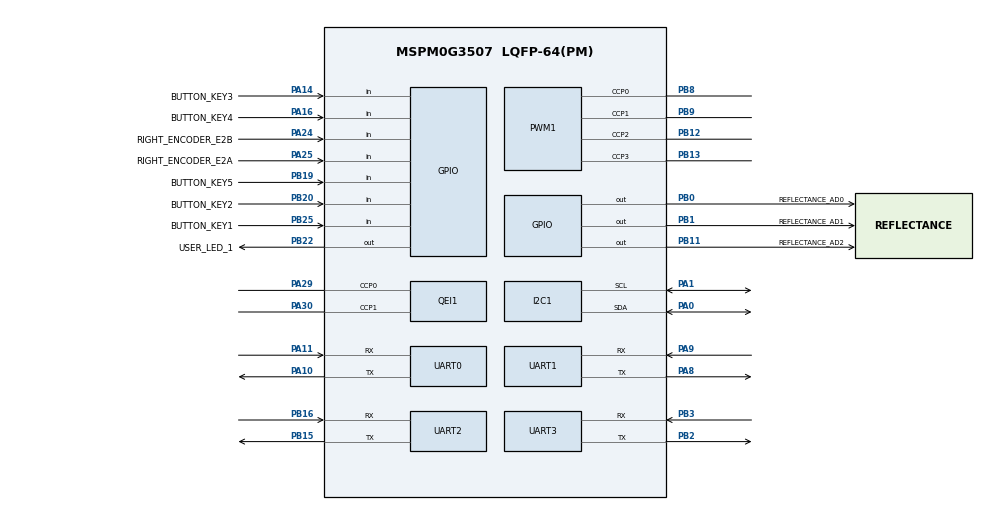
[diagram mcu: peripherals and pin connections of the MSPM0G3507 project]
/**
 * ECHO platform configuration.
 * 80 MHz MCLK, 1 MHz TIMG12 timebase, and Tianmengxing PB22 LED.
 */
//@cliArgs --device "MSPM0G350X" --package "LQFP-64(PM)" --part "Default"
//@v2CliArgs --device "MSPM0G3507" --package "LQFP-64(PM)"
// @cliArgs --board /ti/boards/LP_MSPM0G3507 --rtos freertos

const ProjectConfig = scripting.addModule("/ti/project_config/ProjectConfig");
const ADC12  = scripting.addModule("/ti/driverlib/ADC12", {}, false);
const ADC1   = ADC12.addInstance();
const ADC2   = ADC12.addInstance();
const GPIO   = scripting.addModule("/ti/driverlib/GPIO", {}, false);
const GPIO1  = GPIO.addInstance();
const GPIO2  = GPIO.addInstance();
const GPIO3  = GPIO.addInstance();
const GPIO4  = GPIO.addInstance();
const GPIO5  = GPIO.addInstance();
const I2C    = scripting.addModule("/ti/driverlib/I2C", {}, false);
const I2C1   = I2C.addInstance();
const PWM    = scripting.addModule("/ti/driverlib/PWM", {}, false);
const PWM1   = PWM.addInstance();
const QEI    = scripting.addModule("/ti/driverlib/QEI", {}, false);
const QEI1   = QEI.addInstance();
const SYSCTL = scripting.addModule("/ti/driverlib/SYSCTL");
const TIMER  = scripting.addModule("/ti/driverlib/TIMER", {}, false);
const TIMER1 = TIMER.addInstance();

ProjectConfig.genDisable = true;

const pllClk1Divider = system.clockTree["PLL_CLK1_DIV"];
pllClk1Divider.divideValue = 4;

const pllClk2xDivider = system.clockTree["PLL_CLK2X_DIV"];
pllClk2xDivider.divideValue = 4;

const pllPDivider = system.clockTree["PLL_PDIV"];
pllPDivider.divideValue = 2;

const ulpClkDivider = system.clockTree["UDIV"];
ulpClkDivider.divideValue = 2;

const pllQDivider = system.clockTree["PLL_QDIV"];
pllQDivider.multiplyValue = 10;

const hsclkMux = system.clockTree["HSCLKMUX"];
hsclkMux.inputSelect = "HSCLKMUX_SYSPLL2X";

const mfclkGate = system.clockTree["MFCLKGATE"];
mfclkGate.enable = true;

GPIO1.$name                          = "GPIO_LEDS";
GPIO1.associatedPins[0].$name        = "USER_LED_1";
GPIO1.associatedPins[0].assignedPin  = "22";
GPIO1.associatedPins[0].initialValue = "SET";
GPIO1.associatedPins[0].internalResistor = "PULL_DOWN";
GPIO1.associatedPins[0].pin.$assign  = "PB22";

GPIO2.$name                         = "GPIO_RIGHT_ENCODER";
GPIO2.associatedPins.create(2);
GPIO2.associatedPins[0].$name       = "RIGHT_ENCODER_E2A";
GPIO2.associatedPins[0].direction   = "INPUT";
GPIO2.associatedPins[0].interruptEn = true;
GPIO2.associatedPins[0].polarity    = "RISE";
GPIO2.associatedPins[0].pin.$assign = "PA25";
GPIO2.associatedPins[1].$name       = "RIGHT_ENCODER_E2B";
GPIO2.associatedPins[1].direction   = "INPUT";
GPIO2.associatedPins[1].pin.$assign = "PA24";

GPIO3.$name                         = "GPIO_REFLECTANCE_MUX";
GPIO3.associatedPins.create(3);
GPIO3.associatedPins[0].$name       = "REFLECTANCE_AD0";
GPIO3.associatedPins[0].pin.$assign = "PB0";
GPIO3.associatedPins[1].$name       = "REFLECTANCE_AD1";
GPIO3.associatedPins[1].pin.$assign = "PB1";
GPIO3.associatedPins[2].$name       = "REFLECTANCE_AD2";
GPIO3.associatedPins[2].pin.$assign = "PB11";

GPIO4.$name                         = "GPIO_BUTTONS_A";
GPIO4.associatedPins.create(2);
GPIO4.associatedPins[0].$name       = "BUTTON_KEY3";
GPIO4.associatedPins[0].direction   = "INPUT";
GPIO4.associatedPins[0].internalResistor = "PULL_UP";
GPIO4.associatedPins[0].pin.$assign = "PA14";
GPIO4.associatedPins[1].$name       = "BUTTON_KEY4";
GPIO4.associatedPins[1].direction   = "INPUT";
GPIO4.associatedPins[1].internalResistor = "PULL_UP";
GPIO4.associatedPins[1].pin.$assign = "PA16";

GPIO5.$name                         = "GPIO_BUTTONS_B";
GPIO5.associatedPins.create(3);
GPIO5.associatedPins[0].$name       = "BUTTON_KEY1";
GPIO5.associatedPins[0].direction   = "INPUT";
GPIO5.associatedPins[0].internalResistor = "PULL_UP";
GPIO5.associatedPins[0].pin.$assign = "PB25";
GPIO5.associatedPins[1].$name       = "BUTTON_KEY2";
GPIO5.associatedPins[1].direction   = "INPUT";
GPIO5.associatedPins[1].internalResistor = "PULL_UP";
GPIO5.associatedPins[1].pin.$assign = "PB20";
GPIO5.associatedPins[2].$name       = "BUTTON_KEY5";
GPIO5.associatedPins[2].direction   = "INPUT";
GPIO5.associatedPins[2].internalResistor = "PULL_UP";
GPIO5.associatedPins[2].pin.$assign = "PB19";

ADC1.$name                      = "REFLECTANCE_ADC";
ADC1.sampClkSrc                 = "DL_ADC12_CLOCK_ULPCLK";
ADC1.sampClkDiv                 = "DL_ADC12_CLOCK_DIVIDE_8";
ADC1.adcMem0chansel             = "DL_ADC12_INPUT_CHAN_1";
ADC1.sampleTime0                = "4 us";
ADC1.powerDownMode              = "DL_ADC12_POWER_DOWN_MODE_MANUAL";
ADC1.peripheral.$assign         = "ADC0";
ADC1.peripheral.adcPin1.$assign = "PA26";

ADC2.$name                      = "SUPPLY_ADC";
ADC2.sampClkSrc                 = "DL_ADC12_CLOCK_ULPCLK";
ADC2.sampClkDiv                 = "DL_ADC12_CLOCK_DIVIDE_8";
ADC2.adcMem0chansel             = "DL_ADC12_INPUT_CHAN_4";
ADC2.sampleTime0                = "40 us";
ADC2.powerDownMode              = "DL_ADC12_POWER_DOWN_MODE_MANUAL";
ADC2.peripheral.$assign         = "ADC1";
ADC2.peripheral.adcPin4.$assign = "PB17";

PWM1.$name                          = "CHASSIS_PWM";
PWM1.clockSource                    = "MFCLK";
PWM1.clockPrescale                  = 1;
PWM1.timerCount                     = 399;
PWM1.enableShadowLoad               = true;
PWM1.ccIndex                        = [0, 1, 2, 3];
PWM1.peripheral.$assign             = "TIMA0";
PWM1.peripheral.ccp0Pin.$assign     = "PB8";
PWM1.peripheral.ccp1Pin.$assign     = "PB9";
PWM1.peripheral.ccp2Pin.$assign     = "PB12";
PWM1.peripheral.ccp3Pin.$assign     = "PB13";
PWM1.PWM_CHANNEL_0.$name            = "CHASSIS_PWM_LEFT_IN1";
PWM1.PWM_CHANNEL_0.dutyCycle        = 0;
PWM1.PWM_CHANNEL_0.shadowUpdateMode = "ZERO_EVT";
PWM1.PWM_CHANNEL_1.$name            = "CHASSIS_PWM_LEFT_IN2";
PWM1.PWM_CHANNEL_1.dutyCycle        = 0;
PWM1.PWM_CHANNEL_1.shadowUpdateMode = "ZERO_EVT";
PWM1.PWM_CHANNEL_2.$name            = "CHASSIS_PWM_RIGHT_IN1";
PWM1.PWM_CHANNEL_2.dutyCycle        = 0;
PWM1.PWM_CHANNEL_2.shadowUpdateMode = "ZERO_EVT";
PWM1.PWM_CHANNEL_3.$name            = "CHASSIS_PWM_RIGHT_IN2";
PWM1.PWM_CHANNEL_3.dutyCycle        = 0;
PWM1.PWM_CHANNEL_3.shadowUpdateMode = "ZERO_EVT";

const Board = scripting.addModule("/ti/driverlib/Board", {}, false);
SYSCTL.MCLKSource            = "HSCLK";
SYSCTL.SYSPLL_CLK1En         = true;
SYSCTL.SYSPLL_CLK2XEn        = true;
SYSCTL.SYSPLL_CLK2XDiv       = 1;
SYSCTL.HSCLKSource           = "SYSPLLCLK2X";
SYSCTL.validateClkStatus     = true;
SYSCTL.SYSPLL_Qdiv           = 5;
SYSCTL.MFCLKEn               = true;
SYSCTL.forceDefaultClkConfig = true;
SYSCTL.clockTreeEn           = true;

TIMER1.$name              = "TIMEBASE";
TIMER1.timerClkSrc        = "MFCLK";
TIMER1.timerClkDiv        = 4;
TIMER1.timerClkPrescale   = 1;
TIMER1.timerMode          = "PERIODIC_UP";
TIMER1.timerPeriod        = "4294.967296 s";
TIMER1.timerStartTimer    = false;
TIMER1.peripheral.$assign = "TIMG12";
TIMER1.interrupts         = [];

QEI1.$name                      = "LEFT_ENCODER_QEI";
QEI1.loadValue                  = 0xFFFF;
QEI1.interrupts                 = [];
QEI1.peripheral.$assign         = "TIMG8";
QEI1.peripheral.ccp0Pin.$assign = "PA29";
QEI1.peripheral.ccp1Pin.$assign = "PA30";

I2C1.$name                           = "OLED_I2C";
I2C1.basicClockSourceDivider         = 1;
I2C1.basicEnableController           = true;
I2C1.basicControllerStandardBusSpeed = "Fast";
I2C1.basicControllerBusSpeed         = 400000;
I2C1.peripheral.$assign              = "I2C0";
I2C1.peripheral.sdaPin.$assign       = "PA0";
I2C1.peripheral.sclPin.$assign       = "PA1";
I2C1.sdaPinConfig.$name              = "OLED_I2C_SDA_PIN";
I2C1.sdaPinConfig.enableConfig       = true;
I2C1.sclPinConfig.$name              = "OLED_I2C_SCL_PIN";
I2C1.sclPinConfig.enableConfig       = true;

const UART   = scripting.addModule("/ti/driverlib/UART", {}, false);
const UART0  = UART.addInstance();
const UART1  = UART.addInstance();
const UART2  = UART.addInstance();
const UART3  = UART.addInstance();

const ECHO_DEBUG_UART_BAUD = 230400;
const ECHO_LIDAR_UART_BAUD = 115200;
const ECHO_ESP_LINK_UART_BAUD = 115200;
const ECHO_ZDT_UART_BAUD = 115200;

UART0.$name = "DEBUG_UART";
UART0.profile = "CONFIG_PROFILE_1";
UART0.peripheral.$assign = "UART0";
UART0.targetBaudRate = ECHO_DEBUG_UART_BAUD;
UART0.enableInternalLoopback = false;
UART0.enabledInterrupts = ["DMA_DONE_TX", "EOT_DONE", "RX"];
UART0.enableFIFO = true;
UART0.txFifoThreshold = "DL_UART_TX_FIFO_LEVEL_ONE_ENTRY";
UART0.enabledDMATXTriggers = "DL_UART_DMA_INTERRUPT_TX";
UART0.enableDMATX = true;
UART0.peripheral.rxPin.$assign = "PA11";
UART0.peripheral.txPin.$assign = "PA10";
UART0.DMA_CHANNEL_TX.$name = "DEBUG_UART_TX_DMA";
UART0.DMA_CHANNEL_TX.peripheral.$assign = "DMA_CH3";
UART0.DMA_CHANNEL_TX.addressMode = "b2f";
UART0.DMA_CHANNEL_TX.srcIncDec = "INCREMENT";
UART0.DMA_CHANNEL_TX.dstLength = "BYTE";
UART0.DMA_CHANNEL_TX.srcLength = "BYTE";

UART1.$name = "LIDAR_UART";
UART1.profile = "CONFIG_PROFILE_1";
UART1.peripheral.$assign = "UART1";
UART1.targetBaudRate = ECHO_LIDAR_UART_BAUD;
UART1.enableInternalLoopback = false;
UART1.enabledInterrupts = ["RX"];
UART1.enableFIFO = true;
UART1.rxFifoThreshold = "DL_UART_RX_FIFO_LEVEL_ONE_ENTRY";
UART1.txFifoThreshold = "DL_UART_TX_FIFO_LEVEL_ONE_ENTRY";
UART1.peripheral.rxPin.$assign = "PA9";
UART1.peripheral.txPin.$assign = "PA8";
UART1.rxPinConfig.enableConfig = true;
UART1.rxPinConfig.internalResistor = "PULL_UP";

UART2.$name = "ESP_LINK_UART";
UART2.profile = "CONFIG_PROFILE_1";
UART2.peripheral.$assign = "UART2";
UART2.targetBaudRate = ECHO_ESP_LINK_UART_BAUD;
UART2.enableInternalLoopback = false;
UART2.enabledInterrupts = ["DMA_DONE_RX", "DMA_DONE_TX", "EOT_DONE"];
UART2.enableFIFO = true;
UART2.rxFifoThreshold = "DL_UART_RX_FIFO_LEVEL_ONE_ENTRY";
UART2.txFifoThreshold = "DL_UART_TX_FIFO_LEVEL_EMPTY";
UART2.enabledDMARXTriggers = "DL_UART_DMA_INTERRUPT_RX";
UART2.enableDMARX = true;
UART2.enabledDMATXTriggers = "DL_UART_DMA_INTERRUPT_TX";
UART2.enableDMATX = true;
UART2.peripheral.rxPin.$assign = "PB16";
UART2.peripheral.txPin.$assign = "PB15";
UART2.DMA_CHANNEL_RX.$name = "ESP_LINK_UART_RX_DMA";
UART2.DMA_CHANNEL_RX.peripheral.$assign = "DMA_CH1";
UART2.DMA_CHANNEL_RX.transferMode = "FULL_CH_REPEAT_SINGLE";
UART2.DMA_CHANNEL_RX.addressMode = "f2b";
UART2.DMA_CHANNEL_RX.dstIncDec = "INCREMENT";
UART2.DMA_CHANNEL_RX.dstLength = "BYTE";
UART2.DMA_CHANNEL_RX.srcLength = "BYTE";
UART2.DMA_CHANNEL_TX.$name = "ESP_LINK_UART_TX_DMA";
UART2.DMA_CHANNEL_TX.peripheral.$assign = "DMA_CH2";
UART2.DMA_CHANNEL_TX.addressMode = "b2f";
UART2.DMA_CHANNEL_TX.srcIncDec = "INCREMENT";
UART2.DMA_CHANNEL_TX.dstLength = "BYTE";
UART2.DMA_CHANNEL_TX.srcLength = "BYTE";

UART3.$name = "ZDT_GEN2_UART";
UART3.profile = "CONFIG_PROFILE_1";
UART3.peripheral.$assign = "UART3";
UART3.targetBaudRate = ECHO_ZDT_UART_BAUD;
UART3.enableInternalLoopback = false;
UART3.enabledInterrupts = ["DMA_DONE_TX", "EOT_DONE", "RX"];
UART3.enableFIFO = true;
UART3.txFifoThreshold = "DL_UART_TX_FIFO_LEVEL_ONE_ENTRY";
UART3.enabledDMATXTriggers = "DL_UART_DMA_INTERRUPT_TX";
UART3.enableDMATX = true;
UART3.peripheral.rxPin.$assign = "PB3";
UART3.peripheral.txPin.$assign = "PB2";
UART3.DMA_CHANNEL_TX.$name = "ZDT_GEN2_UART_TX_DMA";
UART3.DMA_CHANNEL_TX.peripheral.$assign = "DMA_CH0";
UART3.DMA_CHANNEL_TX.addressMode = "b2f";
UART3.DMA_CHANNEL_TX.srcIncDec = "INCREMENT";
UART3.DMA_CHANNEL_TX.dstLength = "BYTE";
UART3.DMA_CHANNEL_TX.srcLength = "BYTE";
